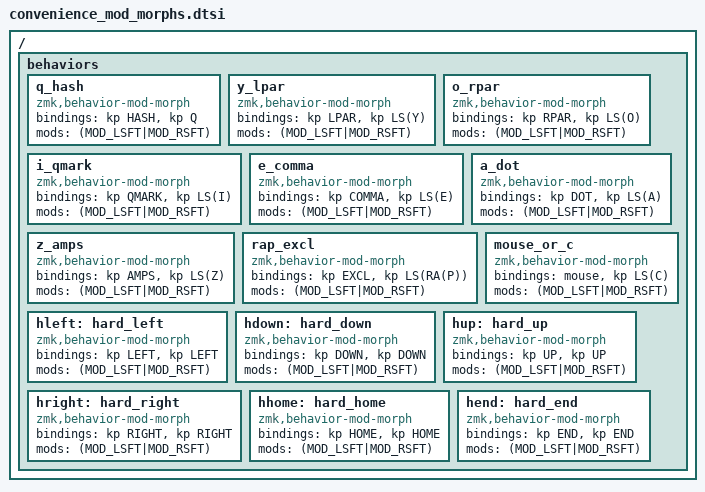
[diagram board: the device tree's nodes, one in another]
/ {
	behaviors {
		
		q_hash: q_hash {
			compatible = "zmk,behavior-mod-morph";
			#binding-cells = <0>;
			bindings = <&kp HASH>, <&kp Q>;
			mods = <(MOD_LSFT|MOD_RSFT)>;
		};

		y_lpar: y_lpar {
			compatible = "zmk,behavior-mod-morph";
			#binding-cells = <0>;
			bindings = <&kp LPAR>, <&kp LS(Y)>;
			mods = <(MOD_LSFT|MOD_RSFT)>;
		};
		
		o_rpar: o_rpar {
			compatible = "zmk,behavior-mod-morph";
			#binding-cells = <0>;
			bindings = <&kp RPAR>, <&kp LS(O)>;
			mods = <(MOD_LSFT|MOD_RSFT)>;
		};
		
		i_qmark: i_qmark {
			compatible = "zmk,behavior-mod-morph";
			#binding-cells = <0>;
			bindings = <&kp QMARK>, <&kp LS(I)>;
			mods = <(MOD_LSFT|MOD_RSFT)>;
		};
		
		e_comma: e_comma {
			compatible = "zmk,behavior-mod-morph";
			#binding-cells = <0>;
			bindings = <&kp COMMA>, <&kp LS(E)>;
			mods = <(MOD_LSFT|MOD_RSFT)>;
		};
		
		a_dot: a_dot {
			compatible = "zmk,behavior-mod-morph";
			#binding-cells = <0>;
			bindings = <&kp DOT>, <&kp LS(A)>;
			mods = <(MOD_LSFT|MOD_RSFT)>;
		};
		
		z_amps: z_amps {
			compatible = "zmk,behavior-mod-morph";
			#binding-cells = <0>;
			bindings = <&kp AMPS>, <&kp LS(Z)>;
			mods = <(MOD_LSFT|MOD_RSFT)>;
		};
		
		rap_excl: rap_excl {
			compatible = "zmk,behavior-mod-morph";
			#binding-cells = <0>;
			bindings = <&kp EXCL>, <&kp LS(RA(P))>;
			mods = <(MOD_LSFT|MOD_RSFT)>;
		};

		mouse_or_c: mouse_or_c {
			compatible = "zmk,behavior-mod-morph";
			#binding-cells = <0>;
			bindings = <&mouse>, <&kp LS(C)>;
			mods = <(MOD_LSFT|MOD_RSFT)>;
		};
		
		hleft: hard_left {
			compatible = "zmk,behavior-mod-morph";
			#binding-cells = <0>;
			bindings = <&kp LEFT>, <&kp LEFT>;
			mods = <(MOD_LSFT|MOD_RSFT)>;
		};

		hdown: hard_down {
			compatible = "zmk,behavior-mod-morph";
			#binding-cells = <0>;
			bindings = <&kp DOWN>, <&kp DOWN>;
			mods = <(MOD_LSFT|MOD_RSFT)>;
		};

		hup: hard_up {
			compatible = "zmk,behavior-mod-morph";
			#binding-cells = <0>;
			bindings = <&kp UP>, <&kp UP>;
			mods = <(MOD_LSFT|MOD_RSFT)>;
		};

		hright: hard_right {
			compatible = "zmk,behavior-mod-morph";
			#binding-cells = <0>;
			bindings = <&kp RIGHT>, <&kp RIGHT>;
			mods = <(MOD_LSFT|MOD_RSFT)>;
		};

		hhome: hard_home {
			compatible = "zmk,behavior-mod-morph";
			#binding-cells = <0>;
			bindings = <&kp HOME>, <&kp HOME>;
			mods = <(MOD_LSFT|MOD_RSFT)>;
		};

		hend: hard_end {
			compatible = "zmk,behavior-mod-morph";
			#binding-cells = <0>;
			bindings = <&kp END>, <&kp END>;
			mods = <(MOD_LSFT|MOD_RSFT)>;
		};

	};
};
